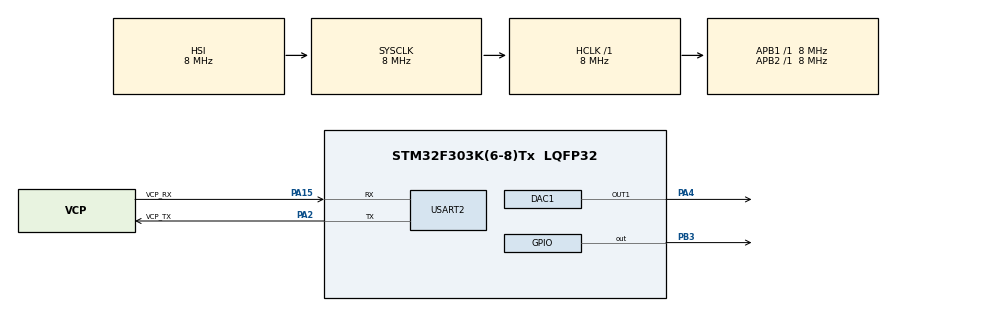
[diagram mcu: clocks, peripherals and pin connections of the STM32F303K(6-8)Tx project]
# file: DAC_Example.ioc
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DAC1.DAC_OutputBuffer=DAC_OUTPUTBUFFER_ENABLE
Mcu.Family=STM32F3
Mcu.Name=STM32F303K(6-8)Tx
Mcu.Package=LQFP32
NVIC.PriorityGroup=NVIC_PRIORITYGROUP_4
PA13.GPIO_Label=SWDIO
PA13.Mode=Serial_Wire
PA13.Signal=SYS_JTMS-SWDIO
PA14.GPIO_Label=SWCLK
PA14.Mode=Serial_Wire
PA14.Signal=SYS_JTCK-SWCLK
PA15.GPIO_Label=VCP_RX
PA15.Mode=Asynchronous
PA15.Signal=USART2_RX
PA2.GPIO_Label=VCP_TX
PA2.Mode=Asynchronous
PA2.Signal=USART2_TX
PA4.Signal=COMP_DAC11_group
PB3.Signal=GPIO_Output
PF0\ /\ OSC_IN.GPIO_Label=MCO
PF0\ /\ OSC_IN.Mode=HSE-External-Clock-Source
PF0\ /\ OSC_IN.Signal=RCC_OSC_IN
ProjectManager.HeapSize=0x200
ProjectManager.StackSize=0x400
ProjectManager.TargetToolchain=SW4STM32
RCC.AHBFreq_Value=8000000
RCC.APB1Freq_Value=8000000
RCC.APB2Freq_Value=8000000
RCC.CortexFreq_Value=8000000
RCC.HSE_VALUE=8000000
RCC.HSI_VALUE=8000000
RCC.SYSCLKFreq_VALUE=8000000
SH.COMP_DAC11_group.0=DAC1_OUT1,DAC_OUT1
USART2.VirtualMode-Asynchronous=VM_ASYNC
board=NUCLEO-F303K8

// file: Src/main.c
/**
  ******************************************************************************
  * @file           : main.c
  * @brief          : Main program body
  ******************************************************************************
  ** This notice applies to any and all portions of this file
  * that are not between comment pairs USER CODE BEGIN and
  * USER CODE END. Other portions of this file, whether
  * inserted by the user or by software development tools
  * are owned by their respective copyright owners.
  *
  * COPYRIGHT(c) 2018 STMicroelectronics
  *
  * Redistribution and use in source and binary forms, with or without modification,
  * are permitted provided that the following conditions are met:
  *   1. Redistributions of source code must retain the above copyright notice,
  *      this list of conditions and the following disclaimer.
  *   2. Redistributions in binary form must reproduce the above copyright notice,
  *      this list of conditions and the following disclaimer in the documentation
  *      and/or other materials provided with the distribution.
  *   3. Neither the name of STMicroelectronics nor the names of its contributors
  *      may be used to endorse or promote products derived from this software
  *      without specific prior written permission.
  *
  * THIS SOFTWARE IS PROVIDED BY THE COPYRIGHT HOLDERS AND CONTRIBUTORS "AS IS"
  * AND ANY EXPRESS OR IMPLIED WARRANTIES, INCLUDING, BUT NOT LIMITED TO, THE
  * IMPLIED WARRANTIES OF MERCHANTABILITY AND FITNESS FOR A PARTICULAR PURPOSE ARE
  * DISCLAIMED. IN NO EVENT SHALL THE COPYRIGHT HOLDER OR CONTRIBUTORS BE LIABLE
  * FOR ANY DIRECT, INDIRECT, INCIDENTAL, SPECIAL, EXEMPLARY, OR CONSEQUENTIAL
  * DAMAGES (INCLUDING, BUT NOT LIMITED TO, PROCUREMENT OF SUBSTITUTE GOODS OR
  * SERVICES; LOSS OF USE, DATA, OR PROFITS; OR BUSINESS INTERRUPTION) HOWEVER
  * CAUSED AND ON ANY THEORY OF LIABILITY, WHETHER IN CONTRACT, STRICT LIABILITY,
  * OR TORT (INCLUDING NEGLIGENCE OR OTHERWISE) ARISING IN ANY WAY OUT OF THE USE
  * OF THIS SOFTWARE, EVEN IF ADVISED OF THE POSSIBILITY OF SUCH DAMAGE.
  *
  ******************************************************************************
  */
#include "main.h"
#include "stm32f3xx_hal.h"
#include "dac.h"
#include "usart.h"
#include "gpio.h"

/* USER CODE BEGIN PV */
/* Private variables ---------------------------------------------------------*/

/* USER CODE END PV */

void SystemClock_Config(void);

/* USER CODE BEGIN PFP */
/* Private function prototypes -----------------------------------------------*/

/* USER CODE END PFP */

int main(void)
{

  /* MCU Configuration----------------------------------------------------------*/

  /* Reset of all peripherals, Initializes the Flash interface and the Systick. */
  HAL_Init();

  /* Configure the system clock */
  SystemClock_Config();

  /* Initialize all configured peripherals */
  MX_GPIO_Init();
  MX_USART2_UART_Init();
  MX_DAC1_Init();
  /* USER CODE BEGIN 2 */
  HAL_DAC_Start(&hdac1, DAC_CHANNEL_1);
  HAL_DAC_SetValue(&hdac1, DAC_CHANNEL_1,DAC_ALIGN_8B_R, 255);
  /* USER CODE END 2 */

  /* Infinite loop */
  /* USER CODE BEGIN WHILE */
  while (1)
  {
	  HAL_GPIO_TogglePin(GPIOB, GPIO_PIN_3);
	  HAL_Delay(1000);
  /* USER CODE END WHILE */

  }

}

void SystemClock_Config(void)
{

  RCC_OscInitTypeDef RCC_OscInitStruct;
  RCC_ClkInitTypeDef RCC_ClkInitStruct;

    /**Initializes the CPU, AHB and APB busses clocks
    */
  RCC_OscInitStruct.OscillatorType = RCC_OSCILLATORTYPE_HSI;
  RCC_OscInitStruct.HSIState = RCC_HSI_ON;
  RCC_OscInitStruct.HSICalibrationValue = 16;
  RCC_OscInitStruct.PLL.PLLState = RCC_PLL_NONE;
  if (HAL_RCC_OscConfig(&RCC_OscInitStruct) != HAL_OK)
  {
    _Error_Handler(__FILE__, __LINE__);
  }

    /**Initializes the CPU, AHB and APB busses clocks
    */
  RCC_ClkInitStruct.ClockType = RCC_CLOCKTYPE_HCLK|RCC_CLOCKTYPE_SYSCLK
                              |RCC_CLOCKTYPE_PCLK1|RCC_CLOCKTYPE_PCLK2;
  RCC_ClkInitStruct.SYSCLKSource = RCC_SYSCLKSOURCE_HSI;
  RCC_ClkInitStruct.AHBCLKDivider = RCC_SYSCLK_DIV1;
  RCC_ClkInitStruct.APB1CLKDivider = RCC_HCLK_DIV1;
  RCC_ClkInitStruct.APB2CLKDivider = RCC_HCLK_DIV1;

  if (HAL_RCC_ClockConfig(&RCC_ClkInitStruct, FLASH_LATENCY_0) != HAL_OK)
  {
    _Error_Handler(__FILE__, __LINE__);
  }

    /**Configure the Systick interrupt time
    */
  HAL_SYSTICK_Config(HAL_RCC_GetHCLKFreq()/1000);

    /**Configure the Systick
    */
  HAL_SYSTICK_CLKSourceConfig(SYSTICK_CLKSOURCE_HCLK);

  /* SysTick_IRQn interrupt configuration */
  HAL_NVIC_SetPriority(SysTick_IRQn, 0, 0);
}

void _Error_Handler(char *file, int line)
{
  while(1)
  {
  }
}

/************************ (C) COPYRIGHT STMicroelectronics *****END OF FILE****/
